VERSION ""

NS_ :

BS_:

BU_:
VAL_TABLE_ Low_Beam_VT 1 "Low Beam Light ON" 0 "Low Beam Light OFF" ;
VAL_TABLE_ High_Beam_VT 1 "High Beam Light ON" 0 "High Beam Light OFF" ;
VAL_TABLE_ Fog_Beam_VT 1 "Fog Light ON" 0 "Fog Light OFF" ;
VAL_TABLE_ Day_Night_VT 1 "Night Time" 0 "Day Time" ;

BO_ 372 Steering_Wheel_Message: 2 Vector__XXX
 SG_ Steering_Wheel_Signal : 0|16@1+ (1,0) [0|65535] "degrees" Vector__XXX

BO_ 344 Sensor_Message: 8 Vector__XXX
 SG_ Light_Sensor_Signal : 32|32@1- (1,0) [0|5] "Volts" Vector__XXX
 SG_ Rain_Sensor_Signal : 0|32@1- (1,0) [0|5] "Volts" Vector__XXX

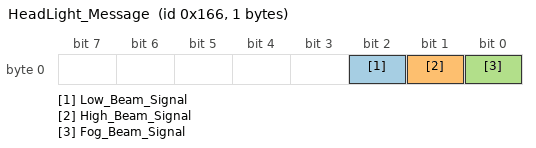
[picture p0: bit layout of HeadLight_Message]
BO_ 358 HeadLight_Message: 1 Vector__XXX
 SG_ Low_Beam_Signal : 2|1@1+ (1,0) [0|1] "Boolean" Vector__XXX
 SG_ High_Beam_Signal : 1|1@1+ (1,0) [0|1] "Boolean" Vector__XXX
 SG_ Fog_Beam_Signal : 0|1@1+ (1,0) [0|1] "Boolean" Vector__XXX

VAL_ 358 Low_Beam_Signal 1 "Low Beam Light ON" 0 "Low Beam Light OFF" ;
VAL_ 358 High_Beam_Signal 1 "High Beam Light ON" 0 "High Beam Light OFF" ;
VAL_ 358 Fog_Beam_Signal 1 "Fog Light ON" 0 "Fog Light OFF" ;
SIG_VALTYPE_ 344 Light_Sensor_Signal : 1;
SIG_VALTYPE_ 344 Rain_Sensor_Signal : 1;
